# STM32L4S9 register map
File version: 2.2
CPU: CM4 r0p1, little endian, MPU, FPU, 4 interrupt priority bits
Registers are 32-bit, read-write, reset 0x0 unless marked. A register's access mark holds for its fields unless they carry their own. Offsets are from the block's base; [hi:lo] are bit positions; {n}, {i} and the like mark numbered series.

## SDMMC1 — Secure digital input/output interface
Base 0x50062400
0x00 POWER — power control register
  [1:0] PWRCTRL
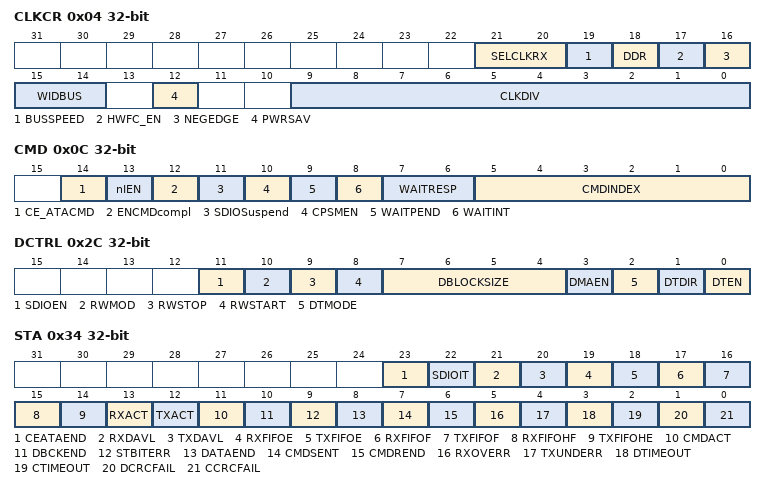
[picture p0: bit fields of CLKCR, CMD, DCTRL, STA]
0x04 CLKCR — SDI clock control register
  [21:20] SELCLKRX — Receive clock selection
  [19] BUSSPEED — Bus speed for selection of SDMMC operating modes
  [18] DDR — Data rate signaling selection
  [17] HWFC_EN — HW Flow Control enable
  [16] NEGEDGE — SDIO_CK dephasing selection bit
  [15:14] WIDBUS — Wide bus mode enable bit
  [12] PWRSAV — Power saving configuration bit
  [9:0] CLKDIV — Clock divide factor
0x08 ARG — argument register
  [31:0] CMDARG — Command argument
0x0C CMD — command register
  [14] CE_ATACMD — CE-ATA command
  [13] nIEN — not Interrupt Enable
  [12] ENCMDcompl — Enable CMD completion
  [11] SDIOSuspend — SD I/O suspend command
  [10] CPSMEN — Command path state machine (CPSM) Enable bit
  [9] WAITPEND — CPSM Waits for ends of data transfer (CmdPend internal signal)
  [8] WAITINT — CPSM waits for interrupt request
  [7:6] WAITRESP — Wait for response bits
  [5:0] CMDINDEX — Command index
0x10 RESPCMD ro — command response register
  [5:0] RESPCMD — Response command index
{0x10+4i} RESP{i} ro (i=1..4) — response 1..4 register
  [31:0] CARDSTATUS{i} — see Table 132
0x24 DTIMER — data timer register
  [31:0] DATATIME — Data timeout period
0x28 DLEN — data length register
  [24:0] DATALENGTH — Data length value
0x2C DCTRL — data control register
  [11] SDIOEN — SD I/O enable functions
  [10] RWMOD — Read wait mode
  [9] RWSTOP — Read wait stop
  [8] RWSTART — Read wait start
  [7:4] DBLOCKSIZE — Data block size
  [3] DMAEN — DMA enable bit
  [2] DTMODE — Data transfer mode selection 1: Stream or SDIO multibyte data transfer
  [1] DTDIR — Data transfer direction selection
  [0] DTEN
0x30 DCOUNT ro — data counter register
  [24:0] DATACOUNT — Data count value
0x34 STA ro — status register
  [23] CEATAEND — CE-ATA command completion signal received for CMD61
  [22] SDIOIT — SDIO interrupt received
  [21] RXDAVL — Data available in receive FIFO
  [20] TXDAVL — Data available in transmit FIFO
  [19] RXFIFOE — Receive FIFO empty
  [18] TXFIFOE — Transmit FIFO empty
  [17] RXFIFOF — Receive FIFO full
  [16] TXFIFOF — Transmit FIFO full
  [15] RXFIFOHF — Receive FIFO half full: there are at least 8 words in the FIFO
  [14] TXFIFOHE — Transmit FIFO half empty: at least 8 words can be written into the FIFO
  [13] RXACT — Data receive in progress
  [12] TXACT — Data transmit in progress
  [11] CMDACT — Command transfer in progress
  [10] DBCKEND — Data block sent/received (CRC check passed)
  [9] STBITERR — Start bit not detected on all data signals in wide bus mode
  [8] DATAEND — Data end (data counter, SDIDCOUNT, is zero)
  [7] CMDSENT — Command sent (no response required)
  [6] CMDREND — Command response received (CRC check passed)
  [5] RXOVERR — Received FIFO overrun error
  [4] TXUNDERR — Transmit FIFO underrun error
  [3] DTIMEOUT — Data timeout
  [2] CTIMEOUT — Command response timeout
  [1] DCRCFAIL — Data block sent/received (CRC check failed)
  [0] CCRCFAIL — Command response received (CRC check failed)
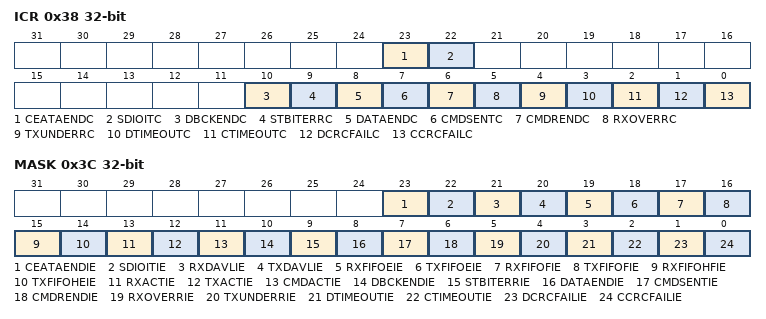
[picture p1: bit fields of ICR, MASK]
0x38 ICR — interrupt clear register
  [23] CEATAENDC — CEATAEND flag clear bit
  [22] SDIOITC — SDIOIT flag clear bit
  [10] DBCKENDC — DBCKEND flag clear bit
  [9] STBITERRC — STBITERR flag clear bit
  [8] DATAENDC — DATAEND flag clear bit
  [7] CMDSENTC — CMDSENT flag clear bit
  [6] CMDRENDC — CMDREND flag clear bit
  [5] RXOVERRC — RXOVERR flag clear bit
  [4] TXUNDERRC — TXUNDERR flag clear bit
  [3] DTIMEOUTC — DTIMEOUT flag clear bit
  [2] CTIMEOUTC — CTIMEOUT flag clear bit
  [1] DCRCFAILC — DCRCFAIL flag clear bit
  [0] CCRCFAILC — CCRCFAIL flag clear bit
0x3C MASK
  [23] CEATAENDIE — CE-ATA command completion signal received interrupt enable
  [22] SDIOITIE — SDIO mode interrupt received interrupt enable
  [21] RXDAVLIE — Data available in Rx FIFO interrupt enable
  [20] TXDAVLIE — Data available in Tx FIFO interrupt enable
  [19] RXFIFOEIE — Rx FIFO empty interrupt enable
  [18] TXFIFOEIE — Tx FIFO empty interrupt enable
  [17] RXFIFOFIE — Rx FIFO full interrupt enable
  [16] TXFIFOFIE — Tx FIFO full interrupt enable
  [15] RXFIFOHFIE — Rx FIFO half full interrupt enable
  [14] TXFIFOHEIE — Tx FIFO half empty interrupt enable
  [13] RXACTIE — Data receive acting interrupt enable
  [12] TXACTIE — Data transmit acting interrupt enable
  [11] CMDACTIE — Command acting interrupt enable
  [10] DBCKENDIE — Data block end interrupt enable
  [9] STBITERRIE — Start bit error interrupt enable
  [8] DATAENDIE — Data end interrupt enable
  [7] CMDSENTIE — Command sent interrupt enable
  [6] CMDRENDIE — Command response received interrupt enable
  [5] RXOVERRIE — Rx FIFO overrun error interrupt enable
  [4] TXUNDERRIE — Tx FIFO underrun error interrupt enable
  [3] DTIMEOUTIE — Data timeout interrupt enable
  [2] CTIMEOUTIE — Command timeout interrupt enable
  [1] DCRCFAILIE — Data CRC fail interrupt enable
  [0] CCRCFAILIE — Command CRC fail interrupt enable
0x48 FIFOCNT ro — FIFO counter register
  [23:0] FIFOCOUNT — Remaining number of words to be written to or read from the FIFO
0x80 FIFO — data FIFO register
  [31:0] FIFOData — Receive and transmit FIFO data

## Notices in the file
Copyright (c) 2025 STMicroelectronics.
SPDX-License-Identifier: Apache-2.0
Licensed under the Apache License, Version 2.0 (the "License");
you may not use this file except in compliance with the License.
You may obtain a copy of the License at
http://www.apache.org/licenses/LICENSE-2.0
Unless required by applicable law or agreed to in writing, software
distributed under the License is distributed on an "AS IS" BASIS,
WITHOUT WARRANTIES OR CONDITIONS OF ANY KIND, either express or implied.
See the License for the specific language governing permissions and
limitations under the License.
